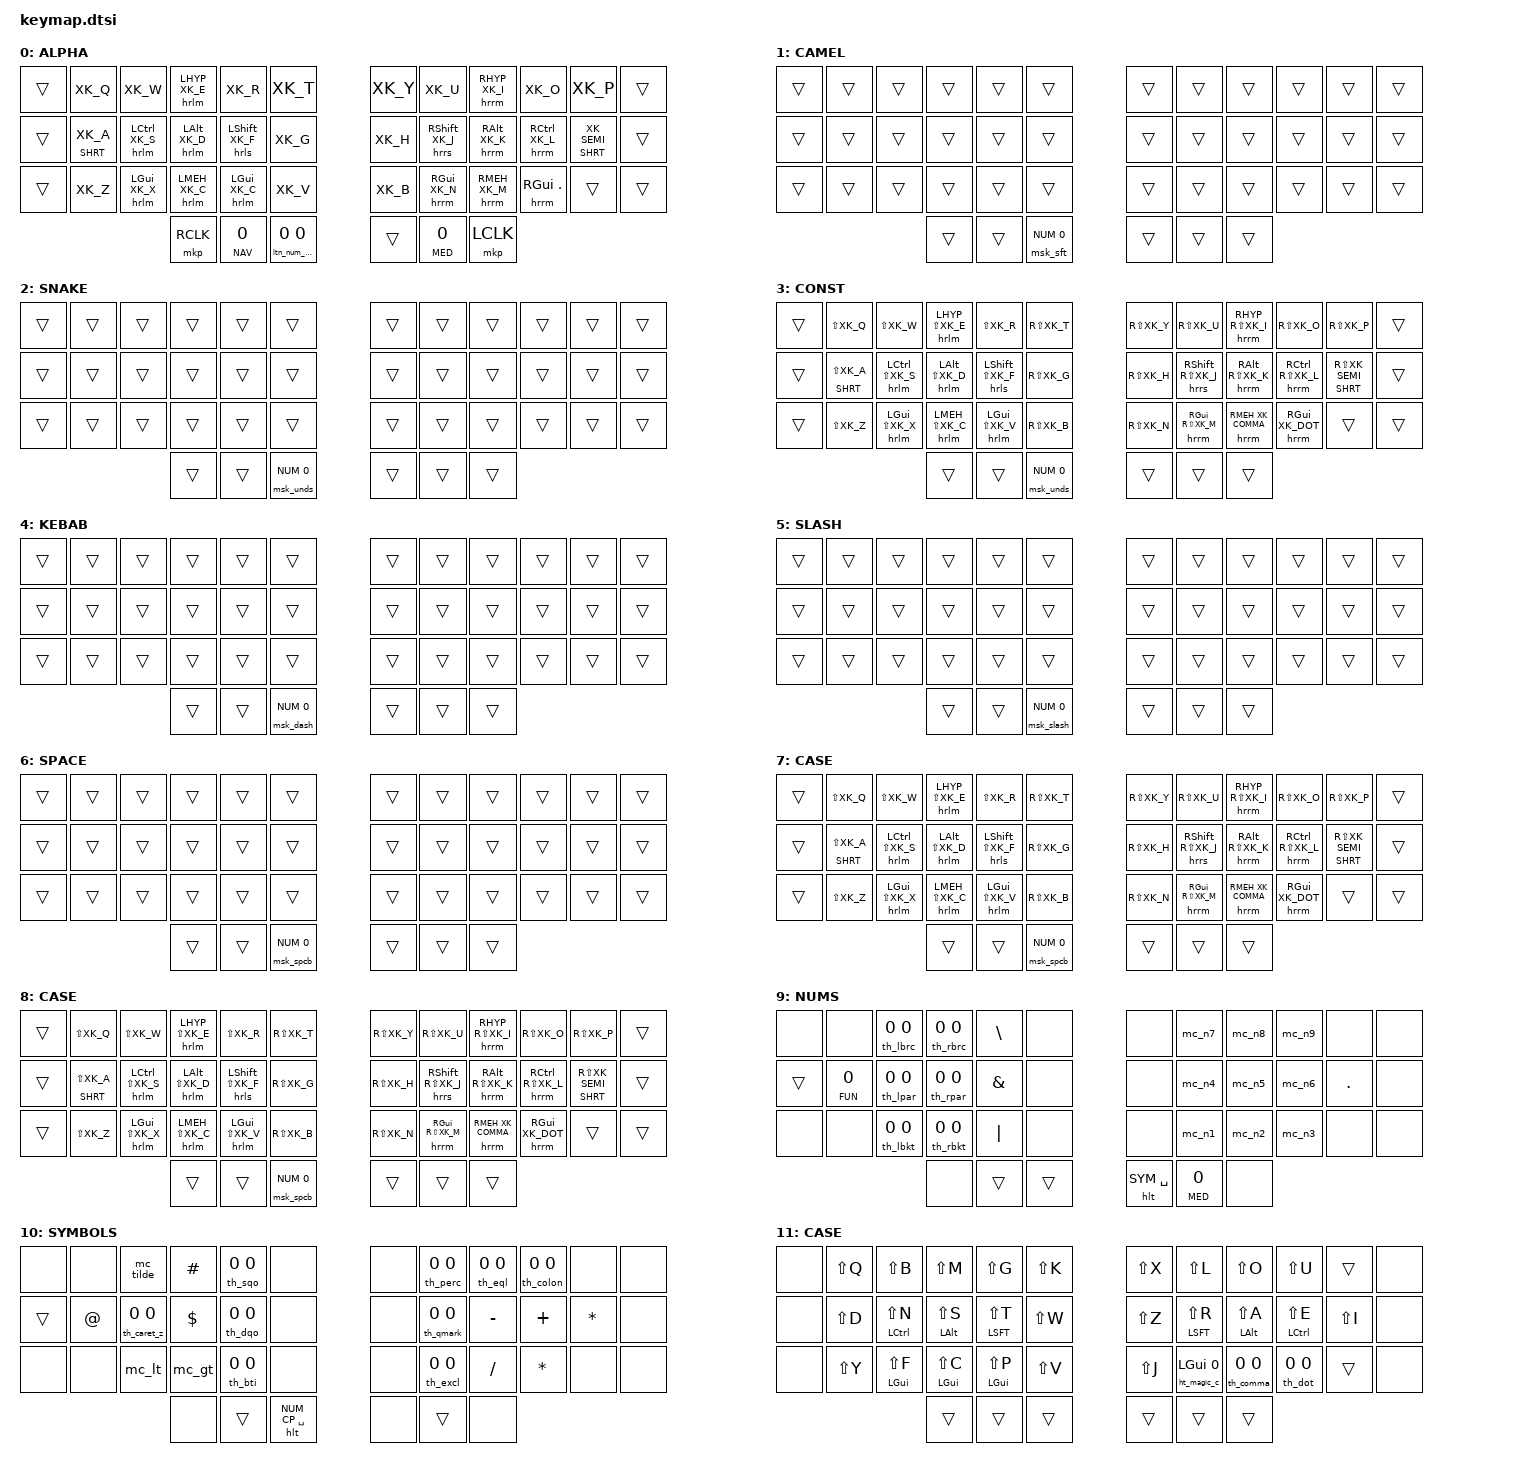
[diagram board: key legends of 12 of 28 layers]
/*
*
* Copyright (c) 2025 Ryan Luckie
* SPDX-License-Identifier: MIT
*
*/
/ {
      keymap {
          compatible = "zmk,keymap";
          default {
               display-name = "ALPHA";
               bindings = <
//╭────────────────────┬────────────────────┬────────────────────┬────────────────────┬────────────────────┬────────────────────┬────────────────────┬────────────────────┬────────────────────┬────────────────────┬────────────────────┬────────────────────╮
   &trans               &kp XK_Q             &kp XK_W             &hrlm LHYP XK_E       &kp XK_R             &kp XK_T             &kp XK_Y             &kp XK_U             &hrrm RHYP XK_I     &kp XK_O               &kp XK_P             &trans
//├────────────────────┼────────────────────┼────────────────────┼────────────────────┼────────────────────┼────────────────────┼────────────────────┼────────────────────┼────────────────────┼────────────────────┼────────────────────┼────────────────────┤
   &trans               &lt SHRT XK_A        &hrlm LCTRL XK_S     &hrlm LALT XK_D      &hrls LSHFT XK_F     &kp XK_G             &kp XK_H             &hrrs RSHFT XK_J     &hrrm RALT XK_K      &hrrm RCTL XK_L      &lt SHRT XK_SEMI     &trans
//├────────────────────┼────────────────────┼────────────────────┼────────────────────┼────────────────────┼────────────────────┼────────────────────┼────────────────────┼────────────────────┼────────────────────┼────────────────────┼────────────────────┤
   &trans               &kp XK_Z             &hrlm LGUI XK_X      &hrlm LMEH XK_C       &hrlm LGUI XK_C      &kp XK_V             &kp XK_B             &hrrm RGUI XK_N      &hrrm RMEH XK_M        &hrrm RGUI DOT      &trans               &trans
//╰────────────────────┴────────────────────┴────────────────────┼────────────────────┼────────────────────┼────────────────────┼────────────────────┼────────────────────┼────────────────────┼────────────────────┴────────────────────┴────────────────────╯
                                                                  &mkp RCLK            &ht_repeat NAV 0     &ltn_num_spc 0 0    &trans             &ht_shift MED 0      &mkp LCLK
//                                                               ╰────────────────────┴────────────────────┴────────────────────┴────────────────────┴────────────────────┴────────────────────╯
                        >;
                };

          camel_case {
               display-name = "CAMEL";
               bindings = <
//╭────────────────────┬────────────────────┬────────────────────┬────────────────────┬────────────────────┬────────────────────┬────────────────────┬────────────────────┬────────────────────┬────────────────────┬────────────────────┬────────────────────╮
   &trans               &trans               &trans               &trans               &trans               &trans               &trans               &trans               &trans               &trans               &trans               &trans
//├────────────────────┼────────────────────┼────────────────────┼────────────────────┼────────────────────┼────────────────────┼────────────────────┼────────────────────┼────────────────────┼────────────────────┼────────────────────┼────────────────────┤
   &trans               &trans               &trans               &trans               &trans               &trans               &trans               &trans               &trans               &trans               &trans               &trans
//├────────────────────┼────────────────────┼────────────────────┼────────────────────┼────────────────────┼────────────────────┼────────────────────┼────────────────────┼────────────────────┼────────────────────┼────────────────────┼────────────────────┤
   &trans               &trans               &trans               &trans               &trans               &trans               &trans               &trans               &trans               &trans               &trans               &trans
//╰────────────────────┴────────────────────┴────────────────────┼────────────────────┼────────────────────┼────────────────────┼────────────────────┼────────────────────┼────────────────────┼────────────────────┴────────────────────┴────────────────────╯
                                                                  &trans               &trans               &msk_sft NUM 0       &trans               &trans               &trans
//                                                               ╰────────────────────┴────────────────────┴────────────────────┴────────────────────┴────────────────────┴────────────────────╯
>;
          };
          snake_case {
               display-name = "SNAKE";
               bindings = <
//╭────────────────────┬────────────────────┬────────────────────┬────────────────────┬────────────────────┬────────────────────┬────────────────────┬────────────────────┬────────────────────┬────────────────────┬────────────────────┬────────────────────╮
   &trans               &trans               &trans               &trans               &trans               &trans               &trans               &trans               &trans               &trans               &trans               &trans
//├────────────────────┼────────────────────┼────────────────────┼────────────────────┼────────────────────┼────────────────────┼────────────────────┼────────────────────┼────────────────────┼────────────────────┼────────────────────┼────────────────────┤
   &trans               &trans               &trans               &trans               &trans               &trans               &trans               &trans               &trans               &trans               &trans               &trans
//├────────────────────┼────────────────────┼────────────────────┼────────────────────┼────────────────────┼────────────────────┼────────────────────┼────────────────────┼────────────────────┼────────────────────┼────────────────────┼────────────────────┤
   &trans               &trans               &trans               &trans               &trans               &trans               &trans               &trans               &trans               &trans               &trans               &trans
//╰────────────────────┴────────────────────┴────────────────────┼────────────────────┼────────────────────┼────────────────────┼────────────────────┼────────────────────┼────────────────────┼────────────────────┴────────────────────┴────────────────────╯
                                                                  &trans               &trans               &msk_unds NUM 0      &trans               &trans               &trans
//                                                               ╰────────────────────┴────────────────────┴────────────────────┴────────────────────┴────────────────────┴────────────────────╯
                           >;
                };

          constant {
               display-name = "CONST";
               bindings = <
//╭────────────────────┬────────────────────┬────────────────────┬────────────────────┬────────────────────┬────────────────────┬────────────────────┬────────────────────┬────────────────────┬────────────────────┬────────────────────┬────────────────────╮
   &trans               &kp LS(XK_Q)         &kp LS(XK_W)         &hrlm LHYP LS(XK_E)  &kp LS(XK_R)         &kp RS(XK_T)         &kp RS(XK_Y)         &kp RS(XK_U)         &hrrm RHYP RS(XK_I)  &kp RS(XK_O)         &kp RS(XK_P)         &trans  
//├────────────────────┼────────────────────┼────────────────────┼────────────────────┼────────────────────┼────────────────────┼────────────────────┼────────────────────┼────────────────────┼────────────────────┼────────────────────┼────────────────────┤
   &trans               &lt SHRT LS(XK_A)    &hrlm LCTRL LS(XK_S) &hrlm LALT LS(XK_D)  &hrls LSHFT LS(XK_F) &kp RS(XK_G)         &kp RS(XK_H)         &hrrs RSHFT RS(XK_J) &hrrm RALT RS(XK_K)  &hrrm RCTL RS(XK_L)  &lt SHRT RS(XK_SEMI) &trans
//├────────────────────┼────────────────────┼────────────────────┼────────────────────┼────────────────────┼────────────────────┼────────────────────┼────────────────────┼────────────────────┼────────────────────┼────────────────────┼────────────────────┤
   &trans               &kp LS(XK_Z)         &hrlm LGUI LS(XK_X)  &hrlm LMEH LS(XK_C)  &hrlm LGUI LS(XK_V)  &kp RS(XK_B)         &kp RS(XK_N)         &hrrm RGUI RS(XK_M)  &hrrm RMEH XK_COMMA  &hrrm RGUI XK_DOT    &trans               &trans
//╰────────────────────┴────────────────────┴────────────────────┼────────────────────┼────────────────────┼────────────────────┼────────────────────┼────────────────────┼────────────────────┼────────────────────┴────────────────────┴────────────────────╯
                                                                  &trans               &trans               &msk_unds NUM 0      &trans         &trans               &trans
//                                                               ╰────────────────────┴────────────────────┴────────────────────┴────────────────────┴────────────────────┴────────────────────╯
                           >;
                };

          kebab_case {
               display-name = "KEBAB";
               bindings = <
//╭────────────────────┬────────────────────┬────────────────────┬────────────────────┬────────────────────┬────────────────────┬────────────────────┬────────────────────┬────────────────────┬────────────────────┬────────────────────┬────────────────────╮
   &trans               &trans               &trans               &trans               &trans               &trans               &trans               &trans               &trans               &trans               &trans               &trans
//├────────────────────┼────────────────────┼────────────────────┼────────────────────┼────────────────────┼────────────────────┼────────────────────┼────────────────────┼────────────────────┼────────────────────┼────────────────────┼────────────────────┤
   &trans               &trans               &trans               &trans               &trans               &trans               &trans               &trans               &trans               &trans               &trans               &trans
//├────────────────────┼────────────────────┼────────────────────┼────────────────────┼────────────────────┼────────────────────┼────────────────────┼────────────────────┼────────────────────┼────────────────────┼────────────────────┼────────────────────┤
   &trans               &trans               &trans               &trans               &trans               &trans               &trans               &trans               &trans               &trans               &trans               &trans
//╰────────────────────┴────────────────────┴────────────────────┼────────────────────┼────────────────────┼────────────────────┼────────────────────┼────────────────────┼────────────────────┼────────────────────┴────────────────────┴────────────────────╯
                                                                  &trans               &trans               &msk_dash NUM 0               &trans               &trans               &trans
//                                                               ╰────────────────────┴────────────────────┴────────────────────┴────────────────────┴────────────────────┴────────────────────╯
                           >;
                };

          slash_case {
               display-name = "SLASH";
               bindings = <
//╭────────────────────┬────────────────────┬────────────────────┬────────────────────┬────────────────────┬────────────────────┬────────────────────┬────────────────────┬────────────────────┬────────────────────┬────────────────────┬────────────────────╮
   &trans               &trans               &trans               &trans               &trans               &trans               &trans               &trans               &trans               &trans               &trans               &trans
//├────────────────────┼────────────────────┼────────────────────┼────────────────────┼────────────────────┼────────────────────┼────────────────────┼────────────────────┼────────────────────┼────────────────────┼────────────────────┼────────────────────┤
   &trans               &trans               &trans               &trans               &trans               &trans               &trans               &trans               &trans               &trans               &trans               &trans
//├────────────────────┼────────────────────┼────────────────────┼────────────────────┼────────────────────┼────────────────────┼────────────────────┼────────────────────┼────────────────────┼────────────────────┼────────────────────┼────────────────────┤
   &trans               &trans               &trans               &trans               &trans               &trans               &trans               &trans               &trans               &trans               &trans               &trans
//╰────────────────────┴────────────────────┴────────────────────┼────────────────────┼────────────────────┼────────────────────┼────────────────────┼────────────────────┼────────────────────┼────────────────────┴────────────────────┴────────────────────╯
                                                                  &trans               &trans               &msk_slash NUM 0     &trans               &trans               &trans
//                                                               ╰────────────────────┴────────────────────┴────────────────────┴────────────────────┴────────────────────┴────────────────────╯
                           >;
                };

          spacing {
               display-name = "SPACE";
               bindings = <
//╭────────────────────┬────────────────────┬────────────────────┬────────────────────┬────────────────────┬────────────────────┬────────────────────┬────────────────────┬────────────────────┬────────────────────┬────────────────────┬────────────────────╮
   &trans               &trans               &trans               &trans               &trans               &trans               &trans               &trans               &trans               &trans               &trans               &trans
//├────────────────────┼────────────────────┼────────────────────┼────────────────────┼────────────────────┼────────────────────┼────────────────────┼────────────────────┼────────────────────┼────────────────────┼────────────────────┼────────────────────┤
   &trans               &trans               &trans               &trans               &trans               &trans               &trans               &trans               &trans               &trans               &trans               &trans
//├────────────────────┼────────────────────┼────────────────────┼────────────────────┼────────────────────┼────────────────────┼────────────────────┼────────────────────┼────────────────────┼────────────────────┼────────────────────┼────────────────────┤
   &trans               &trans               &trans               &trans               &trans               &trans               &trans               &trans               &trans               &trans               &trans               &trans
//╰────────────────────┴────────────────────┴────────────────────┼────────────────────┼────────────────────┼────────────────────┼────────────────────┼────────────────────┼────────────────────┼────────────────────┴────────────────────┴────────────────────╯
                                                                  &trans               &trans               &msk_spcb NUM 0      &trans               &trans               &trans
//                                                               ╰────────────────────┴────────────────────┴────────────────────┴────────────────────┴────────────────────┴────────────────────╯
                           >;
                };

          capsword {
               display-name = "CASE";
               bindings = <
//╭────────────────────┬────────────────────┬────────────────────┬────────────────────┬────────────────────┬────────────────────┬────────────────────┬────────────────────┬────────────────────┬────────────────────┬────────────────────┬────────────────────╮
   &trans               &kp LS(XK_Q)         &kp LS(XK_W)         &hrlm LHYP LS(XK_E)  &kp LS(XK_R)         &kp RS(XK_T)         &kp RS(XK_Y)         &kp RS(XK_U)         &hrrm RHYP RS(XK_I)  &kp RS(XK_O)         &kp RS(XK_P)         &trans  
//├────────────────────┼────────────────────┼────────────────────┼────────────────────┼────────────────────┼────────────────────┼────────────────────┼────────────────────┼────────────────────┼────────────────────┼────────────────────┼────────────────────┤
   &trans               &lt SHRT LS(XK_A)    &hrlm LCTRL LS(XK_S) &hrlm LALT LS(XK_D)  &hrls LSHFT LS(XK_F) &kp RS(XK_G)         &kp RS(XK_H)         &hrrs RSHFT RS(XK_J) &hrrm RALT RS(XK_K)  &hrrm RCTL RS(XK_L)  &lt SHRT RS(XK_SEMI) &trans
//├────────────────────┼────────────────────┼────────────────────┼────────────────────┼────────────────────┼────────────────────┼────────────────────┼────────────────────┼────────────────────┼────────────────────┼────────────────────┼────────────────────┤
   &trans               &kp LS(XK_Z)         &hrlm LGUI LS(XK_X)  &hrlm LMEH LS(XK_C)  &hrlm LGUI LS(XK_V)  &kp RS(XK_B)         &kp RS(XK_N)         &hrrm RGUI RS(XK_M)  &hrrm RMEH XK_COMMA  &hrrm RGUI XK_DOT    &trans               &trans
//╰────────────────────┴────────────────────┴────────────────────┼────────────────────┼────────────────────┼────────────────────┼────────────────────┼────────────────────┼────────────────────┼────────────────────┴────────────────────┴────────────────────╯
                                                                  &trans               &trans               &msk_spcb NUM 0      &trans               &trans               &trans
//                                                               ╰────────────────────┴────────────────────┴────────────────────┴────────────────────┴────────────────────┴────────────────────╯
                           >;
                };

          capsline {
               display-name = "CASE";
               bindings = <
//╭────────────────────┬────────────────────┬────────────────────┬────────────────────┬────────────────────┬────────────────────┬────────────────────┬────────────────────┬────────────────────┬────────────────────┬────────────────────┬────────────────────╮
   &trans               &kp LS(XK_Q)         &kp LS(XK_W)         &hrlm LHYP LS(XK_E)  &kp LS(XK_R)         &kp RS(XK_T)         &kp RS(XK_Y)         &kp RS(XK_U)         &hrrm RHYP RS(XK_I)  &kp RS(XK_O)         &kp RS(XK_P)         &trans  
//├────────────────────┼────────────────────┼────────────────────┼────────────────────┼────────────────────┼────────────────────┼────────────────────┼────────────────────┼────────────────────┼────────────────────┼────────────────────┼────────────────────┤
   &trans               &lt SHRT LS(XK_A)    &hrlm LCTRL LS(XK_S) &hrlm LALT LS(XK_D)  &hrls LSHFT LS(XK_F) &kp RS(XK_G)         &kp RS(XK_H)         &hrrs RSHFT RS(XK_J) &hrrm RALT RS(XK_K)  &hrrm RCTL RS(XK_L)  &lt SHRT RS(XK_SEMI) &trans
//├────────────────────┼────────────────────┼────────────────────┼────────────────────┼────────────────────┼────────────────────┼────────────────────┼────────────────────┼────────────────────┼────────────────────┼────────────────────┼────────────────────┤
   &trans               &kp LS(XK_Z)         &hrlm LGUI LS(XK_X)  &hrlm LMEH LS(XK_C)  &hrlm LGUI LS(XK_V)  &kp RS(XK_B)         &kp RS(XK_N)         &hrrm RGUI RS(XK_M)  &hrrm RMEH XK_COMMA  &hrrm RGUI XK_DOT    &trans               &trans
//╰────────────────────┴────────────────────┴────────────────────┼────────────────────┼────────────────────┼────────────────────┼────────────────────┼────────────────────┼────────────────────┼────────────────────┴────────────────────┴────────────────────╯
                                                                  &trans               &trans               &msk_spcb NUM 0      &trans               &trans               &trans
//                                                               ╰────────────────────┴────────────────────┴────────────────────┴────────────────────┴────────────────────┴────────────────────╯
                           >;
                };

          numbers {
               display-name = "NUMS";
               bindings = <
//╭────────────────────┬────────────────────┬────────────────────┬────────────────────┬────────────────────┬────────────────────┬────────────────────┬────────────────────┬────────────────────┬────────────────────┬────────────────────┬────────────────────╮
   &none                &none                &th_lbrc 0 0         &th_rbrc 0 0         &kp BSLH             &none                &none                &mc_n7               &mc_n8               &mc_n9               &none                &none
//├────────────────────┼────────────────────┼────────────────────┼────────────────────┼────────────────────┼────────────────────┼────────────────────┼────────────────────┼────────────────────┼────────────────────┼────────────────────┼────────────────────┤
   &trans               &lt_deg FUN 0        &th_lpar 0 0         &th_rpar 0 0         &kp AMPS             &none                &none                &mc_n4               &mc_n5               &mc_n6               &kp DOT              &none
//├────────────────────┼────────────────────┼────────────────────┼────────────────────┼────────────────────┼────────────────────┼────────────────────┼────────────────────┼────────────────────┼────────────────────┼────────────────────┼────────────────────┤
   &none                &none                &th_lbkt 0 0         &th_rbkt 0 0         &kp PIPE             &none                &none                &mc_n1               &mc_n2               &mc_n3               &none                &none
//╰────────────────────┴────────────────────┴────────────────────┼────────────────────┼────────────────────┼────────────────────┼────────────────────┼────────────────────┼────────────────────┼────────────────────┴────────────────────┴────────────────────╯
                                                                  &none                &trans               &trans               &hlt SYM SPACE       &lt_n0 MED 0         &none
//                                                               ╰────────────────────┴────────────────────┴────────────────────┴────────────────────┴────────────────────┴────────────────────╯
                           >;
                };

          symbols {
               display-name = "SYMBOLS";
               bindings = <
//╭────────────────────┬────────────────────┬────────────────────┬────────────────────┬────────────────────┬────────────────────┬────────────────────┬────────────────────┬────────────────────┬────────────────────┬────────────────────┬────────────────────╮
   &none                &none                &mc_tilde            &kp HASH             &th_sqo 0 0          &none                &none                &th_perc 0 0         &th_eql 0 0          &th_colon 0 0        &none                &none
//├────────────────────┼────────────────────┼────────────────────┼────────────────────┼────────────────────┼────────────────────┼────────────────────┼────────────────────┼────────────────────┼────────────────────┼────────────────────┼────────────────────┤
   &trans               &kp AT               &th_caret_z 0 0      &kp DOLLAR           &th_dqo 0 0          &none                &none                &th_qmark 0 0        &kp MINUS            &kp PLUS             &kp STAR             &none
//├────────────────────┼────────────────────┼────────────────────┼────────────────────┼────────────────────┼────────────────────┼────────────────────┼────────────────────┼────────────────────┼────────────────────┼────────────────────┼────────────────────┤
   &none                &none                &mc_lt               &mc_gt               &th_bti 0 0          &none                &none                &th_excl 0 0         &kp SLASH            &kp STAR             &none                &none
//╰────────────────────┴────────────────────┴────────────────────┼────────────────────┼────────────────────┼────────────────────┼────────────────────┼────────────────────┼────────────────────┼────────────────────┴────────────────────┴────────────────────╯
                                                                  &none                &trans               &hlt NUM_CP SPACE    &none                &trans               &none 
//                                                               ╰────────────────────┴────────────────────┴────────────────────┴────────────────────┴────────────────────┴────────────────────╯
                           >;
                };

         sentence_case {
               display-name = "CASE";
               bindings = <
//╭────────────────────┬────────────────────┬────────────────────┬────────────────────┬────────────────────┬────────────────────┬────────────────────┬────────────────────┬────────────────────┬────────────────────┬────────────────────┬────────────────────╮
   &none                &kp LS(Q)            &kp LS(B)           &kp LS(M)            &kp LS(G)           &kp LS(K)             &kp LS(X)             &kp LS(L)           &kp LS(O)            &kp LS(U)             &trans               &none
//├────────────────────┼────────────────────┼────────────────────┼────────────────────┼────────────────────┼────────────────────┼────────────────────┼────────────────────┼────────────────────┼────────────────────┼────────────────────┼────────────────────┤
   &none                &kp LS(D)            &mt LCTL LS(N)       &mt LALT LS(S)       &mt LSFT LS(T)      &kp LS(W)             &kp LS(Z)             &mt LSFT LS(R)      &mt LALT LS(A)       &mt LCTL LS(E)       &kp LS(I)            &none 
//├────────────────────┼────────────────────┼────────────────────┼────────────────────┼────────────────────┼────────────────────┼────────────────────┼────────────────────┼────────────────────┼────────────────────┼────────────────────┼────────────────────┤
   &none                &kp LS(Y)            &mt LGUI LS(F)       &mt LGUI LS(C)       &mt LGUI LS(P)      &kp LS(V)             &kp LS(J)             &ht_magic_c LGUI 0  &th_comma 0 0        &th_dot 0 0          &trans               &none
//╰────────────────────┴────────────────────┴────────────────────┼────────────────────┼────────────────────┼────────────────────┼────────────────────┼────────────────────┼────────────────────┼────────────────────┴────────────────────┴────────────────────╯
                                                                  &trans               &trans               &trans               &trans   &trans               &trans
//                                                               ╰────────────────────┴────────────────────┴────────────────────┴────────────────────┴────────────────────┴────────────────────╯
                           >;
                };

          ccedil {
               display-name = "Ç EXT";
               bindings = <
//╭────────────────────┬────────────────────┬────────────────────┬────────────────────┬────────────────────┬────────────────────┬────────────────────┬────────────────────┬────────────────────┬────────────────────┬────────────────────┬────────────────────╮
   &none                &none                &none                &none                &none                &none                &none                &none                &trans               &trans               &none                &none
//├────────────────────┼────────────────────┼────────────────────┼────────────────────┼────────────────────┼────────────────────┼────────────────────┼────────────────────┼────────────────────┼────────────────────┼────────────────────┼────────────────────┤
   &none                &none                &none                &none                &none                &none                &none                &none                &trans               &trans               &none                &none
//├────────────────────┼────────────────────┼────────────────────┼────────────────────┼────────────────────┼────────────────────┼────────────────────┼────────────────────┼────────────────────┼────────────────────┼────────────────────┼────────────────────┤
   &none                &none                &none                &none                &none                &none                &none                &none                &trans               &trans               &none                &none
//╰────────────────────┴────────────────────┴────────────────────┼────────────────────┼────────────────────┼────────────────────┼────────────────────┼────────────────────┼────────────────────┼────────────────────┴────────────────────┴────────────────────╯
                                                                  &none                &trans               &trans               &trans               &trans               &none
//                                                               ╰────────────────────┴────────────────────┴────────────────────┴────────────────────┴────────────────────┴────────────────────╯
                           >;
                };

        

          case_ccedil {
               display-name = "CASE";
               bindings = <
//╭────────────────────┬────────────────────┬────────────────────┬────────────────────┬────────────────────┬────────────────────┬────────────────────┬────────────────────┬────────────────────┬────────────────────┬────────────────────┬────────────────────╮
   &none                &none                &none                &none                &none                &none                &none                &none                &trans               &trans               &none                &none
//├────────────────────┼────────────────────┼────────────────────┼────────────────────┼────────────────────┼────────────────────┼────────────────────┼────────────────────┼────────────────────┼────────────────────┼────────────────────┼────────────────────┤
   &none                &none                &none                &none                &none                &none                &none                &none                &trans               &trans               &none                &none
//├────────────────────┼────────────────────┼────────────────────┼────────────────────┼────────────────────┼────────────────────┼────────────────────┼────────────────────┼────────────────────┼────────────────────┼────────────────────┼────────────────────┤
   &none                &none                &none                &none                &none                &none                &none                &none                &trans               &trans               &none                &none
//╰────────────────────┴────────────────────┴────────────────────┼────────────────────┼────────────────────┼────────────────────┼────────────────────┼────────────────────┼────────────────────┼────────────────────┴────────────────────┴────────────────────╯
                                                                  &trans               &trans               &trans               &trans               &trans               &none
//                                                               ╰────────────────────┴────────────────────┴────────────────────┴────────────────────┴────────────────────┴────────────────────╯
                           >;
                };

          shortcuts {
               display-name = "SHORTCUTS";
               bindings = <
//╭────────────────────┬────────────────────┬────────────────────┬────────────────────┬────────────────────┬────────────────────┬────────────────────┬────────────────────┬────────────────────┬────────────────────┬────────────────────┬────────────────────╮
   &trans               &trans               &trans               &trans               &trans               &trans               &trans               &trans               &trans               &trans               &trans               &trans
//├────────────────────┼────────────────────┼────────────────────┼────────────────────┼────────────────────┼────────────────────┼────────────────────┼────────────────────┼────────────────────┼────────────────────┼────────────────────┼────────────────────┤
   &trans               &trans               &trans               &trans               &trans               &trans               &trans               &trans               &trans               &trans               &trans               &trans
//├────────────────────┼────────────────────┼────────────────────┼────────────────────┼────────────────────┼────────────────────┼────────────────────┼────────────────────┼────────────────────┼────────────────────┼────────────────────┼────────────────────┤
   &trans               &trans               &trans               &trans               &trans               &trans               &trans               &trans               &trans               &trans               &trans               &trans
//╰────────────────────┴────────────────────┴────────────────────┼────────────────────┼────────────────────┼────────────────────┼────────────────────┼────────────────────┼────────────────────┼────────────────────┴────────────────────┴────────────────────╯
                                                                  &trans               &trans               &trans               &trans               &trans               &trans
//                                                               ╰────────────────────┴────────────────────┴────────────────────┴────────────────────┴────────────────────┴────────────────────╯
                           >;
                };

          mehs {
               display-name = "MEHS";
               bindings = <
//╭────────────────────┬────────────────────┬────────────────────┬────────────────────┬────────────────────┬────────────────────┬────────────────────┬────────────────────┬────────────────────┬────────────────────┬────────────────────┬────────────────────╮
   &none                &kp LM(XK_Q)         &kp LM(XK_W)         &kp LM(XK_E)         &kp LM(XK_R)         &kp LM(XK_T)         &kp RM(XK_Y)         &kp RM(XK_U)         &kp RM(XK_I)         &kp RM(XK_O)         &kp RM(XK_P)         &trans   
//├────────────────────┼────────────────────┼────────────────────┼────────────────────┼────────────────────┼────────────────────┼────────────────────┼────────────────────┼────────────────────┼────────────────────┼────────────────────┼────────────────────┤
   &trans               &kp LM(XK_A)        &kp LM(XK_S)         &kp LM(XK_D)         &kp LM(XK_F)         &kp LM(XK_G)          &kp RM(XK_H)         &kp RM(XK_J)         &kp RM(XK_K)         &kp RM(XK_L)         &kp RM(XK_SEMI)      &trans
//├────────────────────┼────────────────────┼────────────────────┼────────────────────┼────────────────────┼────────────────────┼────────────────────┼────────────────────┼────────────────────┼────────────────────┼────────────────────┼────────────────────┤
   &none                &kp LM(XK_Z)         &kp LM(XK_X)         &kp LM(XK_C)         &kp LM(XK_V)         &kp LM(XK_B)         &kp RM(XK_N)         &kp RM(XK_M)         &trans               &trans               &trans               &trans
//╰────────────────────┴────────────────────┴────────────────────┼────────────────────┼────────────────────┼────────────────────┼────────────────────┼────────────────────┼────────────────────┼────────────────────┴────────────────────┴────────────────────╯
                                                                  &trans               &trans               &msk_spcb NUM 0      &trans               &trans               &trans
//                                                               ╰────────────────────┴────────────────────┴────────────────────┴────────────────────┴────────────────────┴────────────────────╯
                           >;
                };
          hypers {
               display-name = "";
               bindings = <
//╭────────────────────┬────────────────────┬────────────────────┬────────────────────┬────────────────────┬────────────────────┬────────────────────┬────────────────────┬────────────────────┬────────────────────┬────────────────────┬────────────────────╮
   &none                &kp LH(XK_Q)         &kp LH(XK_W)         &kp LH(XK_E)         &kp LH(XK_R)         &kp LH(XK_T)         &kp RH(XK_Y)         &kp RH(XK_U)         &kp RH(XK_I)         &kp RH(XK_O)         &kp RH(XK_P)         &trans
//├────────────────────┼────────────────────┼────────────────────┼────────────────────┼────────────────────┼────────────────────┼────────────────────┼────────────────────┼────────────────────┼────────────────────┼────────────────────┼────────────────────┤
   &trans               &kp LH(XK_A)        &kp LH(XK_S)         &kp LH(XK_D)         &kp LH(XK_F)         &kp LH(XK_G)          &kp RH(XK_H)         &kp RH(XK_J)         &kp RH(XK_K)         &kp RH(XK_L)         &kp RH(XK_SEMI)      &trans
//├────────────────────┼────────────────────┼────────────────────┼────────────────────┼────────────────────┼────────────────────┼────────────────────┼────────────────────┼────────────────────┼────────────────────┼────────────────────┼────────────────────┤
   &none                &kp LM(XK_Z)         &kp LM(XK_X)         &kp LM(XK_C)         &kp LM(XK_V)         &kp LM(XK_B)         &kp RM(XK_N)         &kp RM(XK_M)         &trans               &trans               &trans               &trans
//╰────────────────────┴────────────────────┴────────────────────┼────────────────────┼────────────────────┼────────────────────┼────────────────────┼────────────────────┼────────────────────┼────────────────────┴────────────────────┴────────────────────╯
                                                                  &trans               &trans               &msk_spcb NUM 0      &trans               &trans               &trans
//                                                               ╰────────────────────┴────────────────────┴────────────────────┴────────────────────┴────────────────────┴────────────────────╯
                           >;
                };
          plain {
               display-name = "PLAIN";
               bindings = <
//╭────────────────────┬────────────────────┬────────────────────┬────────────────────┬────────────────────┬────────────────────┬────────────────────┬────────────────────┬────────────────────┬────────────────────┬────────────────────┬────────────────────╮
   &none                &kp XK_Q             &kp XK_W             &kp XK_E             &kp XK_R             &kp XK_T             &kp XK_Y             &kp XK_U             &kp XK_I             &kp XK_O             &kp XK_P             &trans
//├────────────────────┼────────────────────┼────────────────────┼────────────────────┼────────────────────┼────────────────────┼────────────────────┼────────────────────┼────────────────────┼────────────────────┼────────────────────┼────────────────────┤
   &none                &lt SHRT XK_A        &kp XK_S             &kp XK_D             &kp XK_F             &kp XK_G             &kp XK_H             &kp XK_J             &kp XK_K             &kp XK_L             &lt SHRT XK_SEMI     &trans
//├────────────────────┼────────────────────┼────────────────────┼────────────────────┼────────────────────┼────────────────────┼────────────────────┼────────────────────┼────────────────────┼────────────────────┼────────────────────┼────────────────────┤
   &none                &kp XK_Z             &kp XK_X             &kp XK_C             &kp XK_V             &kp XK_B             &kp XK_N             &kp XK_M             &trans               &trans               &trans               &trans
//╰────────────────────┴────────────────────┴────────────────────┼────────────────────┼────────────────────┼────────────────────┼────────────────────┼────────────────────┼────────────────────┼────────────────────┴────────────────────┴────────────────────╯
                                                                  &trans               &trans               &msk_spcb NUM 0      &trans               &trans               &trans
//                                                               ╰────────────────────┴────────────────────┴────────────────────┴────────────────────┴────────────────────┴────────────────────╯
                           >;
                };

          nav {
               display-name = "NAV";
               bindings = <
//╭────────────────────┬────────────────────┬────────────────────┬────────────────────┬────────────────────┬────────────────────┬────────────────────┬────────────────────┬────────────────────┬────────────────────┬────────────────────┬────────────────────╮
   &none                &none                &mc_swapper          &mc_tabs             &mc_launcher         &none                &none                &kp TAB              &kp ENTER            &kp ESC              &none                &none
//├────────────────────┼────────────────────┼────────────────────┼────────────────────┼────────────────────┼────────────────────┼────────────────────┼────────────────────┼────────────────────┼────────────────────┼────────────────────┼────────────────────┤
   &trans               &lt TEXT INS         &kp LCTRL            &kp LALT             &kp LSHFT            &none                &none                &kp LEFT             &kp DOWN             &kp UP               &kp RIGHT            &none
//├────────────────────┼────────────────────┼────────────────────┼────────────────────┼────────────────────┼────────────────────┼────────────────────┼────────────────────┼────────────────────┼────────────────────┼────────────────────┼────────────────────┤
   &none                &none                &kp LGUI             &kp LMEH             &kp LGUI             &none                &none                &kp DEL              &kp HOME             &kp END              &none                &none
//╰────────────────────┴────────────────────┴────────────────────┼────────────────────┼────────────────────┼────────────────────┼────────────────────┼────────────────────┼────────────────────┼────────────────────┴────────────────────┴────────────────────╯
                                                                  &none                &trans               &none                &hlt SYM_CP SPACE    &mo MED              &none
//                                                               ╰────────────────────┴────────────────────┴────────────────────┴────────────────────┴────────────────────┴────────────────────╯
                           >;
                };

          nums_copy {
               display-name = "NUMS";
               bindings = <
//╭────────────────────┬────────────────────┬────────────────────┬────────────────────┬────────────────────┬────────────────────┬────────────────────┬────────────────────┬────────────────────┬────────────────────┬────────────────────┬────────────────────╮
   &trans               &trans               &trans               &trans               &trans               &trans               &trans               &trans               &trans               &trans               &trans               &trans
//├────────────────────┼────────────────────┼────────────────────┼────────────────────┼────────────────────┼────────────────────┼────────────────────┼────────────────────┼────────────────────┼────────────────────┼────────────────────┼────────────────────┤
   &trans               &trans               &trans               &trans               &trans               &trans               &trans               &trans               &trans               &trans               &trans               &trans
//├────────────────────┼────────────────────┼────────────────────┼────────────────────┼────────────────────┼────────────────────┼────────────────────┼────────────────────┼────────────────────┼────────────────────┼────────────────────┼────────────────────┤
   &trans               &trans               &trans               &trans               &trans               &trans               &trans               &trans               &trans               &trans               &trans               &trans
//╰────────────────────┴────────────────────┴────────────────────┼────────────────────┼────────────────────┼────────────────────┼────────────────────┼────────────────────┼────────────────────┼────────────────────┴────────────────────┴────────────────────╯
                                                                  &trans               &trans               &trans               &trans               &trans               &trans
//                                                               ╰────────────────────┴────────────────────┴────────────────────┴────────────────────┴────────────────────┴────────────────────╯
                           >;
                };

          symbols_copy {
               display-name = "SYMBOLS";
               bindings = <
//╭────────────────────┬────────────────────┬────────────────────┬────────────────────┬────────────────────┬────────────────────┬────────────────────┬────────────────────┬────────────────────┬────────────────────┬────────────────────┬────────────────────╮
   &none                &none                &mc_tilde            &kp HASH             &th_sqo 0 0          &none                &none                &th_perc 0 0         &th_eql 0 0          &th_colon 0 0        &none                &none
//├────────────────────┼────────────────────┼────────────────────┼────────────────────┼────────────────────┼────────────────────┼────────────────────┼────────────────────┼────────────────────┼────────────────────┼────────────────────┼────────────────────┤
   &trans               &kp AT               &th_caret_z 0 0      &kp DOLLAR           &th_dqo 0 0          &none                &none                &th_qmark 0 0        &kp MINUS            &kp PLUS             &kp STAR             &none
//├────────────────────┼────────────────────┼────────────────────┼────────────────────┼────────────────────┼────────────────────┼────────────────────┼────────────────────┼────────────────────┼────────────────────┼────────────────────┼────────────────────┤
   &none                &none                &mc_lt               &mc_gt               &th_bti 0 0          &none                &none                &th_excl 0 0         &kp SLASH            &kp STAR             &none                &none
//╰────────────────────┴────────────────────┴────────────────────┼────────────────────┼────────────────────┼────────────────────┼────────────────────┼────────────────────┼────────────────────┼────────────────────┴────────────────────┴────────────────────╯
                                                                  &none                &trans               &kp SPACE            &kp SPACE            &trans               &none 
//                                                               ╰────────────────────┴────────────────────┴────────────────────┴────────────────────┴────────────────────┴────────────────────╯
                           >;
                };

          media {
                    display-name = "MEDIA";
                    bindings = <
//╭────────────────────┬────────────────────┬────────────────────┬────────────────────┬────────────────────┬────────────────────┬────────────────────┬────────────────────┬────────────────────┬────────────────────┬────────────────────┬────────────────────╮
   &none                &none                &none                &mkp LCLK            &mkp RCLK            &trans               &trans               &mc_hand             &kp ENTER            &kp ESC              &none                &none
//├────────────────────┼────────────────────┼────────────────────┼────────────────────┼────────────────────┼────────────────────┼────────────────────┼────────────────────┼────────────────────┼────────────────────┼────────────────────┼────────────────────┤
   &none                &none                &mmv MOVE_LEFT       &mmv MOVE_UP         &mmv MOVE_RIGHT      &trans               &trans               &mc_mic              &mt C_MUTE C_VOL_DN  &kp C_VOL_UP         &lt_cam TEXT 0       &none
//├────────────────────┼────────────────────┼────────────────────┼────────────────────┼────────────────────┼────────────────────┼────────────────────┼────────────────────┼────────────────────┼────────────────────┼────────────────────┼────────────────────┤
   &none                &none                &msc SCRL_DOWN       &mmv MOVE_DOWN       &msc SCRL_UP         &trans               &trans               &kp C_PP             &kp C_PREV           &kp C_NEXT           &none                &none
//╰────────────────────┴────────────────────┴────────────────────┼────────────────────┼────────────────────┼────────────────────┼────────────────────┼────────────────────┼────────────────────┼────────────────────┴────────────────────┴────────────────────╯
                                                                  &none                &mo NAV_CP           &kp SPACE            &none                &trans               &none
//                                                               ╰────────────────────┴────────────────────┴────────────────────┴────────────────────┴────────────────────┴────────────────────╯
                           >;
                };

          mouse {
                    display-name = "MOUSE";
                    bindings = <
//╭────────────────────┬────────────────────┬────────────────────┬────────────────────┬────────────────────┬────────────────────┬────────────────────┬────────────────────┬────────────────────┬────────────────────┬────────────────────┬────────────────────╮
   &none                &none                &none                &mkp LCLK            &mkp RCLK            &trans               &trans               &mc_hand             &kp ENTER            &kp ESC              &none                &none
//├────────────────────┼────────────────────┼────────────────────┼────────────────────┼────────────────────┼────────────────────┼────────────────────┼────────────────────┼────────────────────┼────────────────────┼────────────────────┼────────────────────┤
   &none                &none                &mmv MOVE_LEFT       &mmv MOVE_UP         &mmv MOVE_RIGHT      &trans               &trans               &mc_mic              &mt C_MUTE C_VOL_DN  &kp C_VOL_UP         &lt_cam TEXT 0       &none
//├────────────────────┼────────────────────┼────────────────────┼────────────────────┼────────────────────┼────────────────────┼────────────────────┼────────────────────┼────────────────────┼────────────────────┼────────────────────┼────────────────────┤
   &none                &none                &msc SCRL_DOWN       &mmv MOVE_DOWN       &msc SCRL_UP         &trans               &trans               &kp C_PP             &kp C_PREV           &kp C_NEXT           &none                &none
//╰────────────────────┴────────────────────┴────────────────────┼────────────────────┼────────────────────┼────────────────────┼────────────────────┼────────────────────┼────────────────────┼────────────────────┴────────────────────┴────────────────────╯
                                                                  &none                &mo NAV_CP           &kp SPACE            &none                &trans               &none
//                                                               ╰────────────────────┴────────────────────┴────────────────────┴────────────────────┴────────────────────┴────────────────────╯
                           >;
                };                

          nav_copy {
               display-name = "NAV";
               bindings = <
//╭────────────────────┬────────────────────┬────────────────────┬────────────────────┬────────────────────┬────────────────────┬────────────────────┬────────────────────┬────────────────────┬────────────────────┬────────────────────┬────────────────────╮
   &none                &none                &mc_swapper          &mc_tabs             &mc_launcher         &none                &none                &kp TAB              &kp ENTER            &kp ESC              &none                &none
//├────────────────────┼────────────────────┼────────────────────┼────────────────────┼────────────────────┼────────────────────┼────────────────────┼────────────────────┼────────────────────┼────────────────────┼────────────────────┼────────────────────┤
   &trans               &lt TEXT INS         &kp LCTRL            &kp LALT             &kp LSHFT            &none                &none                &kp LEFT             &kp DOWN             &kp UP               &kp RIGHT            &none
//├────────────────────┼────────────────────┼────────────────────┼────────────────────┼────────────────────┼────────────────────┼────────────────────┼────────────────────┼────────────────────┼────────────────────┼────────────────────┼────────────────────┤
   &none                &none                &kp LGUI             &kp LMEH             &kp LGUI             &none                &none                &kp DEL              &kp HOME             &kp END              &none                &none
//╰────────────────────┴────────────────────┴────────────────────┼────────────────────┼────────────────────┼────────────────────┼────────────────────┼────────────────────┼────────────────────┼────────────────────┴────────────────────┴────────────────────╯
                                                                  &none                &trans               &trans               &trans               &trans               &none
//                                                               ╰────────────────────┴────────────────────┴────────────────────┴────────────────────┴────────────────────┴────────────────────╯
                           >;
                };

          text {
               display-name = "TEXT";
               bindings = <
//╭────────────────────┬────────────────────┬────────────────────┬────────────────────┬────────────────────┬────────────────────┬────────────────────┬────────────────────┬────────────────────┬────────────────────┬────────────────────┬────────────────────╮
   &none                &none                &select_home         &select_word         &select_line         &trans               &trans               &kp TAB              &kp ENTER            &kp ESC              &none                &none
//├────────────────────┼────────────────────┼────────────────────┼────────────────────┼────────────────────┼────────────────────┼────────────────────┼────────────────────┼────────────────────┼────────────────────┼────────────────────┼────────────────────┤
   &none                &none                &hsk LCTL LCTL       &hsk LALT LALT       &hsk LSFT LSFT       &trans               &trans               &mc_prev_word        &kp DOWN             &kp UP               &mc_next_word        &none
//├────────────────────┼────────────────────┼────────────────────┼────────────────────┼────────────────────┼────────────────────┼────────────────────┼────────────────────┼────────────────────┼────────────────────┼────────────────────┼────────────────────┤
   &none                &none                &hsk LGUI LGUI       &hsk LGUI LGUI       &hsk LGUI LGUI       &trans               &trans               &mc_del_word         &kp HOME             &kp END              &none                &none
//╰────────────────────┴────────────────────┴────────────────────┼────────────────────┼────────────────────┼────────────────────┼────────────────────┼────────────────────┼────────────────────┼────────────────────┴────────────────────┴────────────────────╯
                                                                  &none                &key_repeat          &none                &none                &key_repeat          &none
//                                                               ╰────────────────────┴────────────────────┴────────────────────┴────────────────────┴────────────────────┴────────────────────╯
                           >;
                };

          funcs {
               display-name = "FUNCS";
               bindings = <
//╭────────────────────┬────────────────────┬────────────────────┬────────────────────┬────────────────────┬────────────────────┬────────────────────┬────────────────────┬────────────────────┬────────────────────┬────────────────────┬────────────────────╮
   &none                &kp XK_F24           &kp XK_F23           &hrlm LHYP XK_F22     &kp XK_F21           &none                &none                &kp XK_F9            &hrrm RHYP XK_F10    &kp XK_F11           &kp XK_F12           &none
//├────────────────────┼────────────────────┼────────────────────┼────────────────────┼────────────────────┼────────────────────┼────────────────────┼────────────────────┼────────────────────┼────────────────────┼────────────────────┼────────────────────┤
   &none                &kp XK_F20           &hrlm LCTRL XK_F19   &hrlm LALT XK_F18    &hrls LSHFT XK_F17   &none                &none                &hrrs RSHFT XK_F5    &hrrm RALT XK_F6     &hrrm RCTRL XK_F7    &kp XK_F8            &none
//├────────────────────┼────────────────────┼────────────────────┼────────────────────┼────────────────────┼────────────────────┼────────────────────┼────────────────────┼────────────────────┼────────────────────┼────────────────────┼────────────────────┤
   &none                &kp XK_F16           &hrlm LGUI XK_F15    &hrlm LMEH XK_F14     &hrlm LGUI XK_F13    &none                &none                &hrlm LGUI XK_F1     &hrrm RMEH XK_F2     &hrrm RGUI XK_F3     &kp XK_F4            &none
//╰────────────────────┴────────────────────┴────────────────────┼────────────────────┼────────────────────┼────────────────────┼────────────────────┼────────────────────┼────────────────────┼────────────────────┴────────────────────┴────────────────────╯
                                                                  &none                &bootloader          &none                &none                &key_repeat          &none
//                                                               ╰────────────────────┴────────────────────┴────────────────────┴────────────────────┴────────────────────┴────────────────────╯
                           >;
                };

          system {
               display-name = "SYS";
               bindings = <
//╭────────────────────┬────────────────────┬────────────────────┬────────────────────┬────────────────────┬────────────────────┬────────────────────┬────────────────────┬────────────────────┬────────────────────┬────────────────────┬────────────────────╮
   &bootloader          &bt BT_DISC 4        &bt BT_DISC 3        &bt BT_DISC 2        &bt BT_DISC 1        &bt BT_DISC 0        &bt BT_DISC 0        &bt BT_DISC 1        &bt BT_DISC 2        &bt BT_DISC 3        &bt BT_DISC 4        &bootloader
//├────────────────────┼────────────────────┼────────────────────┼────────────────────┼────────────────────┼────────────────────┼────────────────────┼────────────────────┼────────────────────┼────────────────────┼────────────────────┼────────────────────┤
   &bt BT_CLR_ALL       &bt BT_SEL 4         &bt BT_SEL 3         &bt BT_SEL 2         &bt BT_SEL 1         &bt BT_SEL 0         &bt BT_SEL 0         &bt BT_SEL 1         &bt BT_SEL 2         &bt BT_SEL 3         &bt BT_SEL 4         &bt BT_CLR_ALL
//├────────────────────┼────────────────────┼────────────────────┼────────────────────┼────────────────────┼────────────────────┼────────────────────┼────────────────────┼────────────────────┼────────────────────┼────────────────────┼────────────────────┤
   &sys_reset           &bt BT_CLR           &bt BT_NXT           &bt BT_PRV           &out OUT_BLE         &out OUT_USB          &out OUT_USB         &out OUT_BLE         &bt BT_PRV           &bt BT_NXT           &bt BT_CLR           &sys_reset
//╰────────────────────┴────────────────────┴────────────────────┼────────────────────┼────────────────────┼────────────────────┼────────────────────┼────────────────────┼────────────────────┼────────────────────┴────────────────────┴────────────────────╯
                                                                  &none                &none                &none                &none                &none                &none 
//                                                               ╰────────────────────┴────────────────────┴────────────────────┴────────────────────┴────────────────────┴────────────────────╯
                           >;
                };
          smart {
               display-name = "SMART";
               bindings = <
//╭────────────────────┬────────────────────┬────────────────────┬────────────────────┬────────────────────┬────────────────────┬────────────────────┬────────────────────┬────────────────────┬────────────────────┬────────────────────┬────────────────────╮
   &none                &none                &none                &tc_smart_word       &tc_smart_line       &none                &none                &mc_vim_replace      &mc_o_esc            &mc_sft_o_esc        &none                &none
//├────────────────────┼────────────────────┼────────────────────┼────────────────────┼────────────────────┼────────────────────┼────────────────────┼────────────────────┼────────────────────┼────────────────────┼────────────────────┼────────────────────┤
   &none                &none                &tc_snake_case       &tc_constant_case    &tc_kebab_case       &none                &none                &kp LS(V)            &kp V                &kp LC(V)            &none                &none
//├────────────────────┼────────────────────┼────────────────────┼────────────────────┼────────────────────┼────────────────────┼────────────────────┼────────────────────┼────────────────────┼────────────────────┼────────────────────┼────────────────────┤
   &none                &none                &tc_slash_case       &tc_pascal_case      &tc_camel_case       &none                &none                &mc_dqt0p            &mc_dqtplusp         &mc_dqtplusy         &none                &none
//╰────────────────────┴────────────────────┴────────────────────┼────────────────────┼────────────────────┼────────────────────┼────────────────────┼────────────────────┼────────────────────┼────────────────────┴────────────────────┴────────────────────╯
                                                                  &trans               &key_repeat          &mc_spc_esc          &trans               &bootloader          &none
//                                                               ╰────────────────────┴────────────────────┴────────────────────┴────────────────────┴────────────────────┴────────────────────╯
                           >;
                };
        };
};
